# MSP430FR6972 register map
Registers are 16-bit, read-write, reset 0x0 unless marked. A register's access mark holds for its fields unless they carry their own. Offsets are from the block's base; [hi:lo] are bit positions; {n}, {i} and the like mark numbered series.

## USCI_B0_SPI_MODE
Base 0x00000640
0x00 UCB0CTL1_SPI 8-bit — USCI B0 Control Register 1
0x01 UCB0CTL0_SPI 8-bit — USCI B0 Control Register 0
0x06 UCB0BR0_SPI 8-bit — USCI B0 Baud Rate 0
0x07 UCB0BR1_SPI 8-bit — USCI B0 Baud Rate 1
0x0C UCB0RXBUF_SPI — USCI B0 Receive Buffer
0x0E UCB0TXBUF_SPI — USCI B0 Transmit Buffer
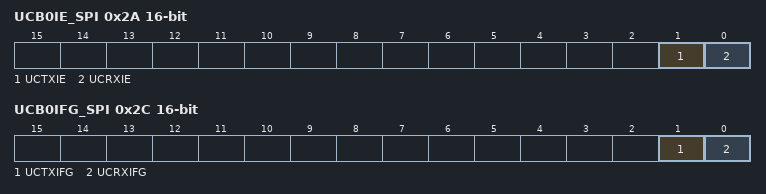
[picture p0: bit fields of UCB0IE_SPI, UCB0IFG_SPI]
0x2A UCB0IE_SPI — USCI B0 Interrupt Enable Register
  [1] UCTXIE — USCI Transmit Interrupt Enable
  [0] UCRXIE — USCI Receive Interrupt Enable
0x2C UCB0IFG_SPI — USCI B0 Interrupt Flags Register
  [1] UCTXIFG — SPI Transmit Interrupt Flag
  [0] UCRXIFG — SPI Receive Interrupt Flag
0x2E UCB0IV_SPI — USCI B0 Interrupt Vector Register

## USCI_B1_I2C_MODE
Base 0x00000680
0x00 UCB1CTL1 8-bit — USCI B1 Control Register 1
0x01 UCB1CTL0 8-bit — USCI B1 Control Register 0
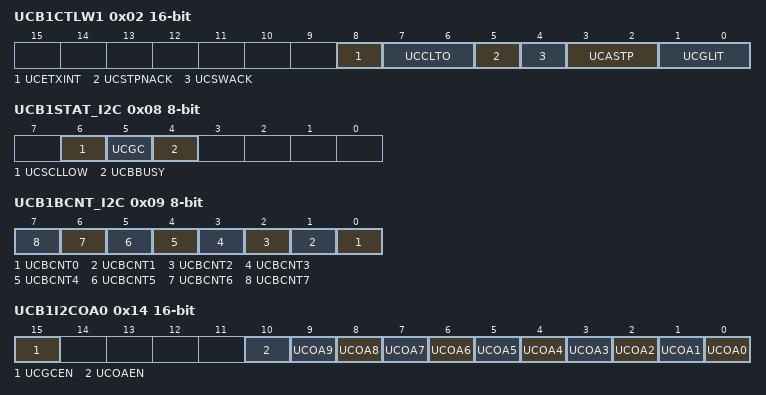
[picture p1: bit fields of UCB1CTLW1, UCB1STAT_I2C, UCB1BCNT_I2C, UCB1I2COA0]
0x02 UCB1CTLW1 — USCI B1 Control Word Register 1
  [8] UCETXINT — USCI Early UCTXIFG0
  [7:6] UCCLTO — USCI Clock low timeout Bit: 1
    {v}=USCI Clock low timeout: {v} (v=0..3)
  [5] UCSTPNACK — USCI Acknowledge Stop last byte
  [4] UCSWACK — USCI Software controlled ACK
  [3:2] UCASTP — USCI Automatic Stop condition generation Bit: 1
    {v}=USCI Automatic Stop condition generation: {v} (v=0..3)
  [1:0] UCGLIT — USCI Deglitch time Bit: 1
    {v}=USCI Deglitch time: {v} (v=0..3)
0x06 UCB1BR0 8-bit — USCI B1 Baud Rate 0
0x07 UCB1BR1 8-bit — USCI B1 Baud Rate 1
0x08 UCB1STAT_I2C 8-bit — USCI B1 Status Register
  [6] UCSCLLOW — SCL low
  [5] UCGC — General Call address received Flag
  [4] UCBBUSY — Bus Busy Flag
0x09 UCB1BCNT_I2C 8-bit — USCI B1 Byte Counter Register
  [n] UCBCNT{n} (n=0..7) — USCI Byte Counter Bit {n}
0x0A UCB1TBCNT — USCI B1 Byte Counter Threshold Register
0x0C UCB1RXBUF — USCI B1 Receive Buffer
0x0E UCB1TXBUF — USCI B1 Transmit Buffer
0x14 UCB1I2COA0 — USCI B1 I2C Own Address 0
  [15] UCGCEN — I2C General Call enable
  [10] UCOAEN — I2C Own Address enable
  [n] UCOA{n} (n=0..9) — I2C Own Address Bit {n}
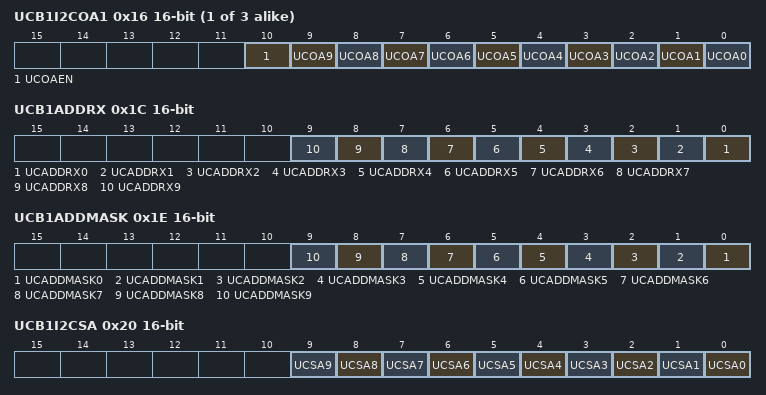
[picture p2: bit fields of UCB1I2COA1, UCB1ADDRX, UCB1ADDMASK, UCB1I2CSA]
{0x14+2i} UCB1I2COA{i} (i=1..3) — USCI B1 I2C Own Address {i}
  [10] UCOAEN — I2C Own Address enable
  [n] UCOA{n} (n=0..9) — I2C Own Address Bit {n}
0x1C UCB1ADDRX — USCI B1 Received Address Register
  [n] UCADDRX{n} (n=0..9) — I2C Receive Address Bit {n}
0x1E UCB1ADDMASK — USCI B1 Address Mask Register
  [n] UCADDMASK{n} (n=0..9) — I2C Address Mask Bit {n}
0x20 UCB1I2CSA — USCI B1 I2C Slave Address
  [n] UCSA{n} (n=0..9) — I2C Slave Address Bit {n}
0x2A UCB1IE — USCI B1 Interrupt Enable Register
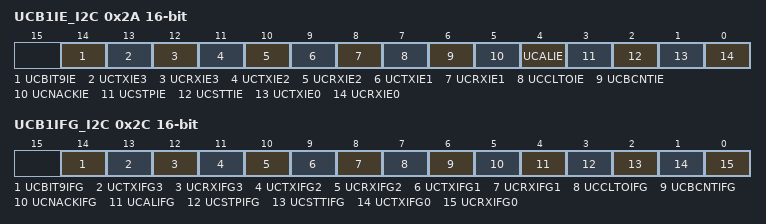
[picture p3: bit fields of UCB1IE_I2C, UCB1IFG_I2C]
0x2A UCB1IE_I2C (alternate view of UCB1IE) — USCI B1 Interrupt Enable Register
  [14] UCBIT9IE — I2C Bit 9 Position Interrupt Enable 3
  [13] UCTXIE3 — I2C Transmit Interrupt Enable 3
  [12] UCRXIE3 — I2C Receive Interrupt Enable 3
  [11] UCTXIE2 — I2C Transmit Interrupt Enable 2
  [10] UCRXIE2 — I2C Receive Interrupt Enable 2
  [9] UCTXIE1 — I2C Transmit Interrupt Enable 1
  [8] UCRXIE1 — I2C Receive Interrupt Enable 1
  [7] UCCLTOIE — I2C Clock Low Timeout interrupt enable
  [6] UCBCNTIE — I2C Automatic stop assertion interrupt enable
  [5] UCNACKIE — I2C NACK Condition interrupt enable
  [4] UCALIE — I2C Arbitration Lost interrupt enable
  [3] UCSTPIE — I2C STOP Condition interrupt enable
  [2] UCSTTIE — I2C START Condition interrupt enable
  [1] UCTXIE0 — I2C Transmit Interrupt Enable 0
  [0] UCRXIE0 — I2C Receive Interrupt Enable 0
0x2C UCB1IFG — USCI B1 Interrupt Flags Register
0x2C UCB1IFG_I2C (alternate view of UCB1IFG) — USCI B1 Interrupt Flags Register
  [14] UCBIT9IFG — I2C Bit 9 Possition Interrupt Flag 3
  [13] UCTXIFG3 — I2C Transmit Interrupt Flag 3
  [12] UCRXIFG3 — I2C Receive Interrupt Flag 3
  [11] UCTXIFG2 — I2C Transmit Interrupt Flag 2
  [10] UCRXIFG2 — I2C Receive Interrupt Flag 2
  [9] UCTXIFG1 — I2C Transmit Interrupt Flag 1
  [8] UCRXIFG1 — I2C Receive Interrupt Flag 1
  [7] UCCLTOIFG — I2C Clock low Timeout interrupt Flag
  [6] UCBCNTIFG — I2C Byte counter interrupt flag
  [5] UCNACKIFG — I2C NACK Condition interrupt Flag
  [4] UCALIFG — I2C Arbitration Lost interrupt Flag
  [3] UCSTPIFG — I2C STOP Condition interrupt Flag
  [2] UCSTTIFG — I2C START Condition interrupt Flag
  [1] UCTXIFG0 — I2C Transmit Interrupt Flag 0
  [0] UCRXIFG0 — I2C Receive Interrupt Flag 0
0x2E UCB1IV — USCI B1 Interrupt Vector Register
